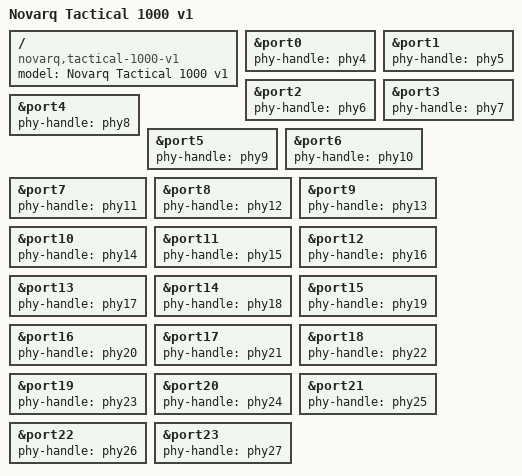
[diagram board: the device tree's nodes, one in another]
// SPDX-License-Identifier: GPL-2.0-or-later OR MIT

/dts-v1/;

#include "lan969x_tactical-1000.dtsi"

/ {
	model = "Novarq Tactical 1000 v1";
	compatible = "novarq,tactical-1000-v1", "microchip,lan969x";
};

&port0 {
	phy-handle = <&phy4>;
};

&port1 {
	phy-handle = <&phy5>;
};

&port2 {
	phy-handle = <&phy6>;
};

&port3 {
	phy-handle = <&phy7>;
};

&port4 {
	phy-handle = <&phy8>;
};

&port5 {
	phy-handle = <&phy9>;
};

&port6 {
	phy-handle = <&phy10>;
};

&port7 {
	phy-handle = <&phy11>;
};

&port8 {
	phy-handle = <&phy12>;
};

&port9 {
	phy-handle = <&phy13>;
};

&port10 {
	phy-handle = <&phy14>;
};

&port11 {
	phy-handle = <&phy15>;
};

&port12 {
	phy-handle = <&phy16>;
};

&port13 {
	phy-handle = <&phy17>;
};

&port14 {
	phy-handle = <&phy18>;
};

&port15 {
	phy-handle = <&phy19>;
};

&port16 {
	phy-handle = <&phy20>;
};

&port17 {
	phy-handle = <&phy21>;
};

&port18 {
	phy-handle = <&phy22>;
};

&port19 {
	phy-handle = <&phy23>;
};

&port20 {
	phy-handle = <&phy24>;
};

&port21 {
	phy-handle = <&phy25>;
};

&port22 {
	phy-handle = <&phy26>;
};

&port23 {
	phy-handle = <&phy27>;
};
